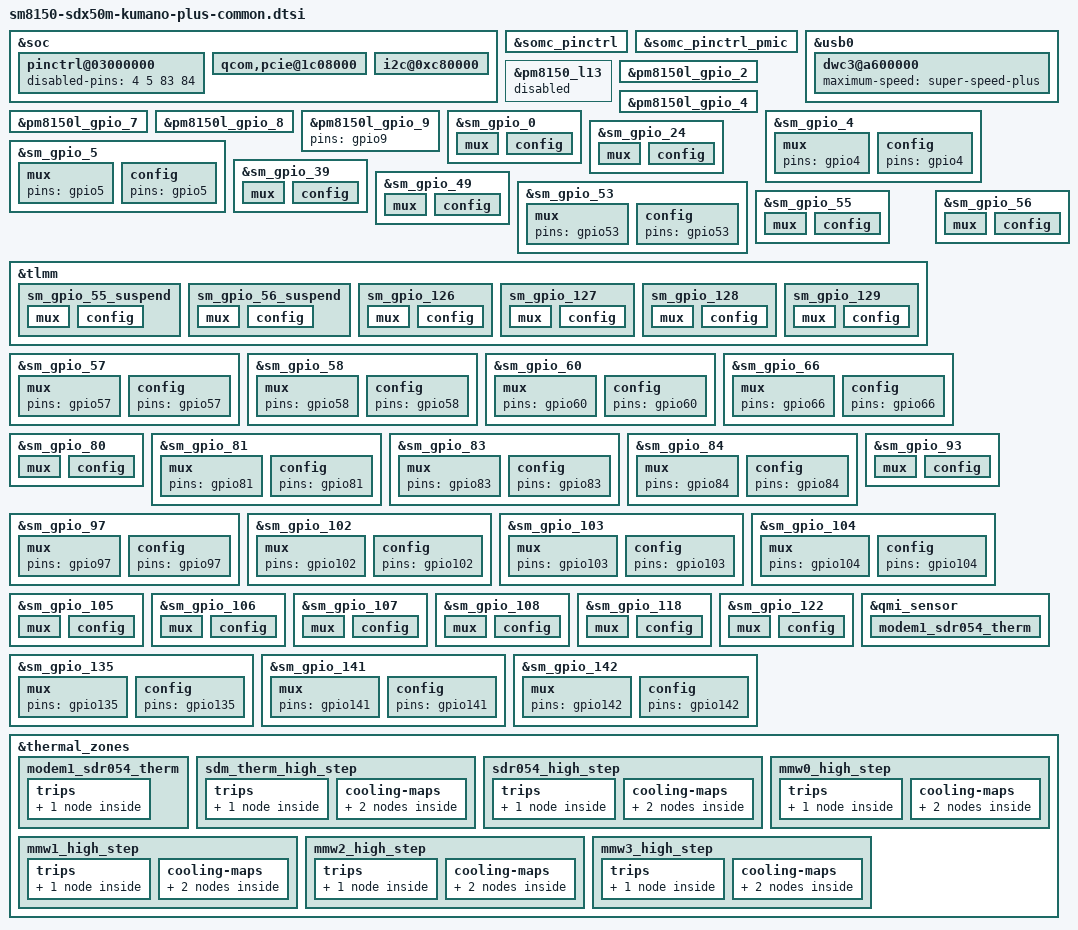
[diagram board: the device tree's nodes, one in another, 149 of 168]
/* arch/arm64/boot/dts/somc/sm8150-sdx50m-kumano-plus-common.dtsi
 *
 * This program is free software; you can redistribute it and/or modify
 * it under the terms of the GNU General Public License version 2 and
 * only version 2 as published by the Free Software Foundation.
 *
 * This program is distributed in the hope that it will be useful,
 * but WITHOUT ANY WARRANTY; without even the implied warranty of
 * MERCHANTABILITY or FITNESS FOR A PARTICULAR PURPOSE.  See the
 * GNU General Public License for more details.
 */

#include "sm8150-kumano-common.dtsi"

&soc {
	pinctrl@03000000 {
		disabled-pins = <4 5 83 84>;
	};

	qcom,pcie@1c08000 {
		status = "ok";
	};

	/* I2C: QUP17 */
	i2c@0xc80000 {
		pinctrl-0 = <&sm_gpio_55 &sm_gpio_56>;
		pinctrl-1 = <&sm_gpio_55_suspend &sm_gpio_56_suspend>;
		qcom,clk-freq-out = <400000>;
		status = "okay";
	};
};

&somc_pinctrl {
	/* If product specific default setting is needed,
	fill pinctrl-1 value in <product>.dtsi */
	pinctrl-1 = <&sm_gpio_0 &sm_gpio_4 &sm_gpio_5 &sm_gpio_24
		     &sm_gpio_39 &sm_gpio_49 &sm_gpio_53 &sm_gpio_55
		     &sm_gpio_56 &sm_gpio_57 &sm_gpio_58 &sm_gpio_60
		     &sm_gpio_66 &sm_gpio_80 &sm_gpio_81 &sm_gpio_83
		     &sm_gpio_84 &sm_gpio_93 &sm_gpio_97 &sm_gpio_102
		     &sm_gpio_103 &sm_gpio_104 &sm_gpio_105 &sm_gpio_106
		     &sm_gpio_107 &sm_gpio_108 &sm_gpio_118 /*&sm_gpio_122*/
		     &sm_gpio_126 &sm_gpio_127 &sm_gpio_128 &sm_gpio_129
		     &sm_gpio_135 &sm_gpio_141 &sm_gpio_142>;
};

&somc_pinctrl_pmic {
	/* If product specific default setting is needed,
	fill pinctrl-1 value in <product>.dtsi */
	pinctrl-1 = <&pm8150l_gpio_2 &pm8150l_gpio_4
		     &pm8150l_gpio_7 &pm8150l_gpio_8 &pm8150l_gpio_9>;
};

&usb0 {
	dwc3@a600000 {
		maximum-speed = "super-speed-plus";
	};
};

/* Regulator config */
&pm8150_l13 {
	status = "disabled";
};

/* GPIO_2: CP_SENSOR_PWR_EN */
&pm8150l_gpio_2 {
	pins = "gpio2";
	function = "normal";
	/delete-property/ bias-high-impedance;
	output-high;
	drive-push-pull;
	qcom,drive-strength = <3>; /* High */
	power-source = <0>;
};

/* GPIO_4: 5G_RF_ID_EXTENSION */
&pm8150l_gpio_4 {
	pins = "gpio4";
	function = "normal";
	/delete-property/ bias-high-impedance;
	input-enable;
	bias-pull-down;
	power-source = <0>;
};

/* GPIO_7 : BOP_HP_EN */
&pm8150l_gpio_7 {
	pins = "gpio7";
	function = "normal";
	/delete-property/ bias-high-impedance;
	input-enable;
	bias-pull-down;
	power-source = <1>;
};

/* GPIO_8 : NC */
&pm8150l_gpio_8 {
	pins = "gpio8";
	function = "normal";
	bias-high-impedance; /* DISABLE GPIO_8 */
	/delete-property/ output-low;
	/delete-property/ drive-push-pull;
	/delete-property/ qcom,drive-strength;
	/delete-property/ power-source;
};

/* GPIO_9 : 5G_PON_RESET_N(Follow QC) */
&pm8150l_gpio_9 {
	pins = "gpio9";
	/delete-property/ function;
	/delete-property/ bias-high-impedance;
};


/* GPIO_0 : NFC_ESE_SPI_MISO */
&sm_gpio_0 {
	mux {
		pins = "gpio0";
		function = "qup0";
	};

	config {
		pins = "gpio0";
		drive-strength = <2>;
		/delete-property/ bias-disable;
		bias-pull-down;
	};
};

/* GPIO_4 : SDX50_5G_IPC_UART1_RX(Follow QC) */
&sm_gpio_4 {
	mux {
		pins = "gpio4";
		/delete-property/ function;
	};

	config {
		pins = "gpio4";
		/delete-property/ drive-strength;
		/delete-property/ bias-pull-down;
		/delete-property/ input-enable;
	};
};

/* GPIO_5 : SDX50_5G_IPC_UART1_TX(Follow QC) */
&sm_gpio_5 {
	mux {
		pins = "gpio5";
		/delete-property/ function;
	};

	config {
		pins = "gpio5";
		/delete-property/ drive-strength;
		/delete-property/ bias-pull-down;
		/delete-property/ input-enable;
	};
};

/* GPIO_24 : CP_SENSOR_INT_N */
&sm_gpio_24 {
	mux {
		pins = "gpio24";
		function = "gpio";
	};

	config {
		pins = "gpio24";
		drive-strength = <2>;
		/delete-property/ bias-pull-down;
		bias-pull-up;
		input-enable;
	};
};

/* GPIO_39 : CP_SENSOR2_INT_N */
&sm_gpio_39 {
	mux {
		pins = "gpio39";
		function = "gpio";
	};

	config {
		pins = "gpio39";
		drive-strength = <2>;
		/delete-property/ bias-pull-down;
		bias-pull-up;
		input-enable;
	};
};

/* GPIO_49 : NC */
&sm_gpio_49 {
	mux {
		pins = "gpio49";
		function = "gpio";
	};

	config {
		pins = "gpio49";
		drive-strength = <2>;
		/delete-property/ bias-disable;
		bias-pull-down;
		/delete-property/ output-low;
		input-enable;
	};
};

/* GPIO_53 : MDM2AP_ERR_FATAL(Follow QC) */
&sm_gpio_53 {
	mux {
		pins = "gpio53";
		/delete-property/ function;
	};

	config {
		pins = "gpio53";
		/delete-property/ drive-strength;
		/delete-property/ bias-pull-down;
		/delete-property/ input-enable;
	};
};

/* GPIO_55 : CP_SENSOR_I2C_SDA */
&sm_gpio_55 {
	mux {
		pins = "gpio55";
		function = "qup17";
	};

	config {
		pins = "gpio55";
		drive-strength = <2>;
		/delete-property/ bias-pull-down;
		bias-disable;
		/delete-property/ input-enable;
	};
};

&tlmm {
	/* GPIO_55 : CP_SENSOR_I2C_SDA (Suspend) */
	sm_gpio_55_suspend: sm_gpio_55_suspend {
		mux {
			pins = "gpio55";
			function = "gpio";
		};

		config {
			pins = "gpio55";
			drive-strength = <2>;
			bias-disable;
			input-enable;
		};
	};
};

/* GPIO_56 : CP_SENSOR_I2C_SCL */
&sm_gpio_56 {
	mux {
		pins = "gpio56";
		function = "qup17";
	};

	config {
		pins = "gpio56";
		drive-strength = <2>;
		/delete-property/ bias-pull-down;
		bias-disable;
		/delete-property/ input-enable;
	};
};

&tlmm {
	/* GPIO_56 : CP_SENSOR_I2C_SCL (Suspend) */
	sm_gpio_56_suspend: sm_gpio_56_suspend {
		mux {
			pins = "gpio56";
			function = "gpio";
		};

		config {
			pins = "gpio56";
			drive-strength = <2>;
			bias-disable;
			input-enable;
		};
	};
};

/* GPIO_57 : SDX_5G_CTI_TRIG_IN(Follow QC) */
&sm_gpio_57 {
	mux {
		pins = "gpio57";
		/delete-property/ function;
	};

	config {
		pins = "gpio57";
		/delete-property/ drive-strength;
		/delete-property/ bias-pull-down;
		/delete-property/ input-enable;
	};
};

/* GPIO_58 : SDX_5G_CTI_TRIG_OUT(Follow QC) */
&sm_gpio_58 {
	mux {
		pins = "gpio58";
		/delete-property/ function;
	};

	config {
		pins = "gpio58";
		/delete-property/ drive-strength;
		/delete-property/ bias-pull-down;
		/delete-property/ input-enable;
	};
};

/* GPIO_60 : 4G_5G_SYNC(Follow QC) */
&sm_gpio_60 {
	mux {
		pins = "gpio60";
		/delete-property/ function;
	};

	config {
		pins = "gpio60";
		/delete-property/ drive-strength;
		/delete-property/ bias-pull-down;
		/delete-property/ input-enable;
	};
};

/* GPIO_66 : SDM_GRFC_10(Follow QC) */
&sm_gpio_66 {
	mux {
		pins = "gpio66";
		/delete-property/ function;
	};

	config {
		pins = "gpio66";
		/delete-property/ drive-strength;
		/delete-property/ bias-pull-down;
		/delete-property/ input-enable;
	};
};

/* GPIO_80 : NC */
&sm_gpio_80 {
	mux {
		pins = "gpio80";
		function = "gpio";
	};

	config {
		pins = "gpio80";
		drive-strength = <2>;
		/delete-property/ bias-disable;
		bias-pull-down;
		/delete-property/ output-low;
		input-enable;
	};
};

/* GPIO_81 : GPS_5G_BLANKING(Follow QC) */
&sm_gpio_81 {
	mux {
		pins = "gpio81";
		/delete-property/ function;
	};

	config {
		pins = "gpio81";
		/delete-property/ drive-strength;
		/delete-property/ bias-pull-down;
		/delete-property/ input-enable;
	};
};

/* GPIO_83 : SDX50_5G_IPC_UART2_TX(Follow QC) */
&sm_gpio_83 {
	mux {
		pins = "gpio83";
		/delete-property/ function;
	};

	config {
		pins = "gpio83";
		/delete-property/ drive-strength;
		/delete-property/ bias-pull-down;
		/delete-property/ input-enable;
	};
};

/* GPIO_84 : SDX50_5G_IPC_UART2_RX(Follow QC) */
&sm_gpio_84 {
	mux {
		pins = "gpio84";
		/delete-property/ function;
	};

	config {
		pins = "gpio84";
		/delete-property/ drive-strength;
		/delete-property/ bias-pull-down;
		/delete-property/ input-enable;
	};
};

/* GPIO_93 : CP_SENSOR3_INT_N */
&sm_gpio_93 {
	mux {
		pins = "gpio93";
		function = "gpio";
	};

	config {
		pins = "gpio93";
		drive-strength = <2>;
		/delete-property/ bias-pull-down;
		bias-pull-up;
		input-enable;
	};
};

/* GPIO_97 : MSM_BUCK_QUIET_MODE(Follow QC) */
&sm_gpio_97 {
	mux {
		pins = "gpio97";
		/delete-property/ function;
	};

	config {
		pins = "gpio97";
		/delete-property/ drive-strength;
		/delete-property/ bias-pull-down;
		/delete-property/ input-enable;
	};
};

/* GPIO_102 : PCIE1_SDX_RST_N(Follow QC) */
&sm_gpio_102 {
	mux {
		pins = "gpio102";
		/delete-property/ function;
	};

	config {
		pins = "gpio102";
		/delete-property/ drive-strength;
		/delete-property/ bias-pull-down;
		/delete-property/ input-enable;
	};
};

/* GPIO_103 : PCIE1_SDX_CLKREQ_N(Follow QC) */
&sm_gpio_103 {
	mux {
		pins = "gpio103";
		/delete-property/ function;
	};

	config {
		pins = "gpio103";
		/delete-property/ drive-strength;
		/delete-property/ bias-pull-down;
		/delete-property/ input-enable;
	};
};

/* GPIO_104 : PCIE1_SDX_WAKE_N(Follow QC) */
&sm_gpio_104 {
	mux {
		pins = "gpio104";
		/delete-property/ function;
	};

	config {
		pins = "gpio104";
		/delete-property/ drive-strength;
		/delete-property/ bias-pull-down;
		/delete-property/ input-enable;
	};
};

/* GPIO_105: NC */
&sm_gpio_105 {
	mux {
		pins = "gpio105";
		function = "gpio";
	};

	config {
		pins = "gpio105";
		drive-strength = <2>;
		bias-pull-down;
		input-enable;
	};
};

/* GPIO_106: NC */
&sm_gpio_106 {
	mux {
		pins = "gpio106";
		function = "gpio";
	};

	config {
		pins = "gpio106";
		drive-strength = <2>;
		bias-pull-down;
		input-enable;
	};
};

/* GPIO_107: NC */
&sm_gpio_107 {
	mux {
		pins = "gpio107";
		function = "gpio";
	};

	config {
		pins = "gpio107";
		drive-strength = <2>;
		bias-pull-down;
		input-enable;
	};
};

/* GPIO_108: NC */
&sm_gpio_108 {
	mux {
		pins = "gpio108";
		function = "gpio";
	};

	config {
		pins = "gpio108";
		drive-strength = <2>;
		/delete-property/ bias-disable;
		bias-pull-down;
		input-enable;
	};
};

/* GPIO_118 : NC */
&sm_gpio_118 {
	mux {
		pins = "gpio118";
		function = "gpio";
	};

	config {
		pins = "gpio118";
		drive-strength = <2>;
		/delete-property/ bias-disable;
		bias-pull-down;
		input-enable;
	};
};

/* GPIO_122 : TS_INT_N */
&sm_gpio_122 {
	mux {
		pins = "gpio122";
		function = "gpio";
	};

	config {
		pins = "gpio122";
		drive-strength = <2>;
		bias-disable;
		input-enable;
	};
};

&tlmm {
	/* GPIO_126 : NC */
	sm_gpio_126: sm_gpio_126 {
		mux {
			pins = "gpio126";
			function = "gpio";
		};

		config {
			pins = "gpio126";
			drive-strength = <2>;
			bias-pull-down;
			input-enable;
		};
	};

	/* GPIO_127 : NC */
	sm_gpio_127: sm_gpio_127 {
		mux {
			pins = "gpio127";
			function = "gpio";
		};

		config {
			pins = "gpio127";
			drive-strength = <2>;
			bias-pull-down;
			input-enable;
		};
	};

	/* GPIO_128 : NC */
	sm_gpio_128: sm_gpio_128 {
		mux {
			pins = "gpio128";
			function = "gpio";
		};

		config {
			pins = "gpio128";
			drive-strength = <2>;
			bias-pull-down;
			input-enable;
		};
	};

	/* GPIO_129 : NC */
	sm_gpio_129: sm_gpio_129 {
		mux {
			pins = "gpio129";
			function = "gpio";
		};

		config {
			pins = "gpio129";
			drive-strength = <2>;
			bias-pull-down;
			input-enable;
		};
	};
};

/* GPIO_135 : AP2MDM_STATUS(Follow QC) */
&sm_gpio_135 {
	mux {
		pins = "gpio135";
		/delete-property/ function;
	};

	config {
		pins = "gpio135";
		/delete-property/ drive-strength;
		/delete-property/ bias-pull-down;
		/delete-property/ input-enable;
	};
};

/* GPIO_141 : AP2MDM_ERR_FATAL(Follow QC) */
&sm_gpio_141 {
	mux {
		pins = "gpio141";
		/delete-property/ function;
	};

	config {
		pins = "gpio141";
		/delete-property/ drive-strength;
		/delete-property/ bias-pull-down;
		/delete-property/ input-enable;
	};
};

/* GPIO_142 : MDM2AP_STATUS(Follow QC) */
&sm_gpio_142 {
	mux {
		pins = "gpio142";
		/delete-property/ function;
	};

	config {
		pins = "gpio142";
		/delete-property/ drive-strength;
		/delete-property/ bias-pull-down;
		/delete-property/ input-enable;
	};
};

&qmi_sensor {
	modem1_sdr054_therm {
		qcom,instance-id = <100>;
		qcom,qmi-sensor-names = "sdr054_therm";
	};
};

&thermal_zones {
	modem1_sdr054_therm {
		polling-delay-passive = <0>;
		polling-delay = <0>;
		thermal-governor = "user_space";
		thermal-sensors = <&qmi_sensor 113>;
		trips {
			active-config0 {
				temperature = <125000>;
				hysteresis = <1000>;
				type = "passive";
			};
		};
	};

	sdm_therm_high_step {
		polling-delay-passive = <0>;
		polling-delay = <0>;
		thermal-sensors = <&pm8150l_adc_tm ADC_AMUX_THM2_PU2>;
		thermal-governor = "step_wise";
		trips {
			sdm_modem1_0: sdm_modem1_0 {
				temperature = <60000>;
				hysteresis = <12000>;
				type = "passive";
			};
		};
		cooling-maps {
			sdm_modem1_cdev0_0 {
				trip = <&sdm_modem1_0>;
				cooling-device = <&modem1_pa 3 3>;
			};
			sdm_modem1_cdev0_1 {
				trip = <&sdm_modem1_0>;
				cooling-device = <&modem1_skin 3 3>;
			};
		};
	};

	sdr054_high_step {
		polling-delay-passive = <0>;
		polling-delay = <0>;
		thermal-sensors = <&qmi_sensor 113>;
		thermal-governor = "step_wise";
		trips {
			sdr054_modem1_0: sdr054_modem1_0 {
				temperature = <120000>;
				hysteresis = <5000>;
				type = "passive";
			};
		};
		cooling-maps {
			sdr054_modem1_cdev0_0 {
				trip = <&sdr054_modem1_0>;
				cooling-device = <&modem1_pa 3 3>;
			};
			sdr054_modem1_cdev0_1 {
				trip = <&sdr054_modem1_0>;
				cooling-device = <&modem1_skin 3 3>;
			};
		};
	};

	mmw0_high_step {
		polling-delay-passive = <0>;
		polling-delay = <0>;
		thermal-sensors = <&qmi_sensor 106>;
		thermal-governor = "step_wise";
		trips {
			mmw0_0: mmw0_0 {
				temperature = <70000>;
				hysteresis = <14000>;
				type = "passive";
			};
		};
		cooling-maps {
			mmw0_cdev0_0 {
				trip = <&mmw0_0>;
				cooling-device = <&modem1_pa 3 3>;
			};
			mmw0_cdev0_1 {
				trip = <&mmw0_0>;
				cooling-device = <&modem1_skin 3 3>;
			};
		};
	};

	mmw1_high_step {
		polling-delay-passive = <0>;
		polling-delay = <0>;
		thermal-sensors = <&qmi_sensor 107>;
		thermal-governor = "step_wise";
		trips {
			mmw1_0: mmw1_0 {
				temperature = <66000>;
				hysteresis = <13000>;
				type = "passive";
			};
		};
		cooling-maps {
			mmw1_cdev0_0 {
				trip = <&mmw1_0>;
				cooling-device = <&modem1_pa 3 3>;
			};
			mmw1_cdev0_1 {
				trip = <&mmw1_0>;
				cooling-device = <&modem1_skin 3 3>;
			};
		};
	};

	mmw2_high_step {
		polling-delay-passive = <0>;
		polling-delay = <0>;
		thermal-sensors = <&qmi_sensor 108>;
		thermal-governor = "step_wise";
		trips {
			mmw2_0: mmw2_0 {
				temperature = <82000>;
				hysteresis = <14000>;
				type = "passive";
			};
		};
		cooling-maps {
			mmw2_cdev0_0 {
				trip = <&mmw2_0>;
				cooling-device = <&modem1_pa 3 3>;
			};
			mmw2_cdev0_1 {
				trip = <&mmw2_0>;
				cooling-device = <&modem1_skin 3 3>;
			};
		};
	};

	mmw3_high_step {
		polling-delay-passive = <0>;
		polling-delay = <0>;
		thermal-sensors = <&qmi_sensor 109>;
		thermal-governor = "step_wise";
		trips {
			mmw3_0: mmw3_0 {
				temperature = <70000>;
				hysteresis = <14000>;
				type = "passive";
			};
		};
		cooling-maps {
			mmw3_cdev0_0 {
				trip = <&mmw3_0>;
				cooling-device = <&modem1_pa 3 3>;
			};
			mmw3_cdev0_1 {
				trip = <&mmw3_0>;
				cooling-device = <&modem1_skin 3 3>;
			};
		};
	};
};
